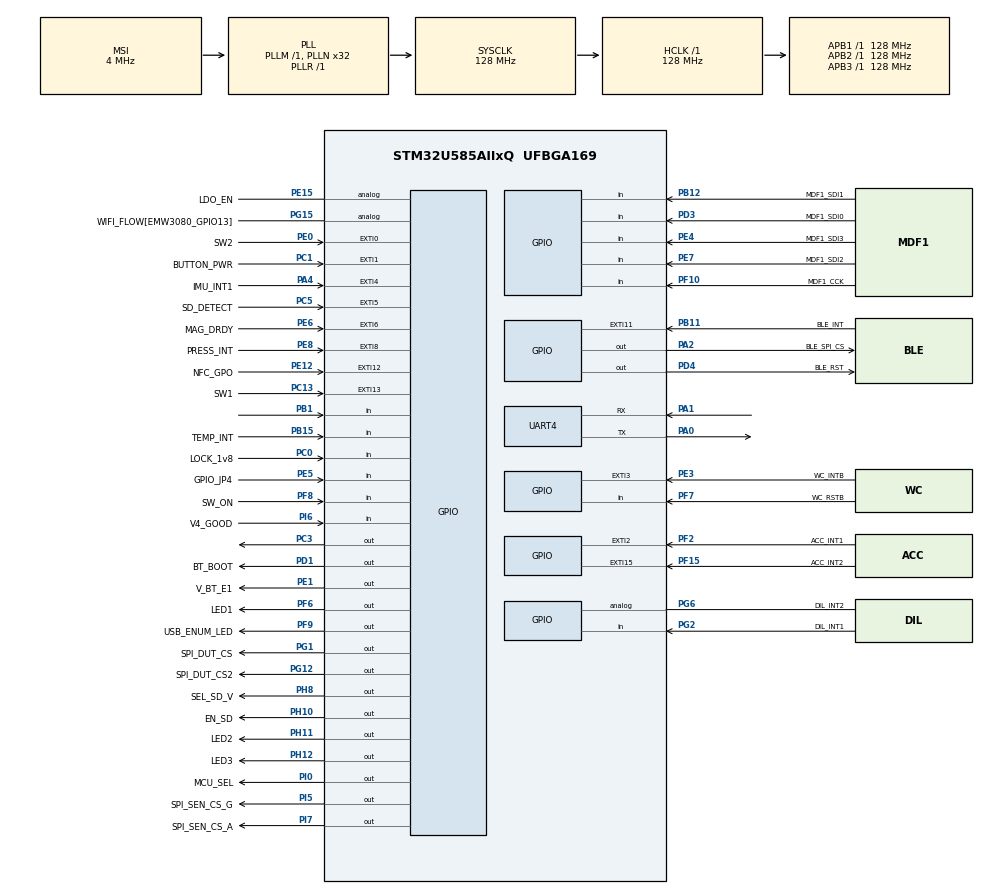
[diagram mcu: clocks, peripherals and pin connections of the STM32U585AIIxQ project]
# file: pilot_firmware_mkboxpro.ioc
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CORTEX_M33_NS.userName=CORTEX_M33
Mcu.Family=STM32U5
Mcu.Name=STM32U585AIIxQ
Mcu.Package=UFBGA169
NVIC.EXTI0_IRQn=true\:7\:0\:true\:false\:true\:true\:true\:false
NVIC.EXTI11_IRQn=true\:0\:0\:false\:false\:true\:true\:true\:true
NVIC.EXTI13_IRQn=true\:0\:0\:false\:false\:true\:true\:true\:true
NVIC.EXTI15_IRQn=true\:7\:0\:true\:false\:true\:true\:true\:false
NVIC.EXTI1_IRQn=true\:7\:0\:true\:false\:true\:true\:true\:false
NVIC.EXTI2_IRQn=true\:7\:0\:true\:false\:true\:true\:true\:false
NVIC.EXTI3_IRQn=true\:7\:0\:true\:false\:true\:true\:true\:false
NVIC.EXTI4_IRQn=true\:7\:0\:true\:false\:true\:true\:true\:false
NVIC.EXTI5_IRQn=true\:7\:0\:true\:false\:true\:true\:true\:false
NVIC.EXTI6_IRQn=true\:7\:0\:true\:false\:true\:true\:true\:false
NVIC.EXTI8_IRQn=true\:7\:0\:true\:false\:true\:true\:true\:true
NVIC.PriorityGroup=NVIC_PRIORITYGROUP_4
PA0.Mode=Asynchronous
PA0.Signal=UART4_TX
PA1.Mode=Asynchronous
PA1.Signal=UART4_RX
PA10.Signal=SAI1_SD_A
PA11.GPIO_Speed=GPIO_SPEED_FREQ_VERY_HIGH
PA11.Signal=USB_OTG_FS_DM
PA12.GPIO_Speed=GPIO_SPEED_FREQ_VERY_HIGH
PA12.PinAttribute=Free
PA12.Signal=USB_OTG_FS_DP
PA13\ (JTMS/SWDIO).Signal=DEBUG_JTMS-SWDIO
PA14\ (JTCK/SWCLK).Signal=DEBUG_JTCK-SWCLK
PA2.GPIO_Label=BLE_SPI_CS
PA2.Signal=GPIO_Output
PA4.GPIO_Label=IMU_INT1
PA4.Signal=GPXTI4
PA5.GPIO_PuPd=GPIO_PULLUP
PA5.GPIO_Speed=GPIO_SPEED_FREQ_HIGH
PA5.Signal=SPI1_SCK
PA6.GPIO_Speed=GPIO_SPEED_FREQ_HIGH
PA6.PinAttribute=Free
PA6.Signal=SPI1_MISO
PA7.GPIO_Speed=GPIO_SPEED_FREQ_HIGH
PA7.Signal=SPI1_MOSI
PA8.Signal=SAI1_SCK_A
PA9.Signal=SAI1_FS_A
PB0.GPIO_Label=VBATT
PB0.Signal=ADC1_IN15
PB1.Signal=GPIO_Input
PB10.Signal=S_TIM2_CH3
PB11.GPIO_Label=BLE_INT
PB11.Signal=GPXTI11
PB12.GPIO_Label=MDF1_SDI1
PB12.Signal=GPIO_Input
PB13.Signal=I2C2_SCL
PB14.Signal=I2C2_SDA
PB15.GPIO_Label=TEMP_INT
PB15.Signal=GPIO_Input
PB3\ (JTDO/TRACESWO).Signal=DEBUG_JTDO-SWO
PB5.GPIO_Speed=GPIO_SPEED_FREQ_HIGH
PB5.Signal=SPI3_MOSI
PB6.Signal=I2C1_SCL
PB7.Signal=UART4_CTS
PB8.Signal=SDMMC1_CKIN
PB9.Signal=SDMMC1_CDIR
PC0.GPIO_Label=LOCK_1v8
PC0.Signal=GPIO_Input
PC1.GPIO_Label=BUTTON_PWR
PC1.Signal=GPXTI1
PC10.Signal=SDMMC1_D2
PC11.Signal=SDMMC1_D3
PC12.Signal=SDMMC1_CK
PC13.GPIO_Label=SW1
PC13.Signal=GPXTI13
PC14-OSC32_IN\ (PC14).Signal=RCC_OSC32_IN
PC15-OSC32_OUT\ (PC15).Signal=RCC_OSC32_OUT
PC3.PinState=GPIO_PIN_SET
PC3.Signal=GPIO_Output
PC5.GPIO_Label=SD_DETECT
PC5.Signal=GPXTI5
PC6.Signal=SDMMC1_D0DIR
PC7.Signal=SDMMC1_D123DIR
PC8.PinAttribute=Free
PC8.Signal=SDMMC1_D0
PC9.PinAttribute=Free
PC9.Signal=SDMMC1_D1
PD1.GPIO_Label=BT_BOOT
PD1.Signal=GPIO_Output
PD12.Signal=I2C4_SCL
PD13.Signal=I2C4_SDA
PD2.Signal=SDMMC1_CMD
PD3.GPIO_Label=MDF1_SDI0
PD3.Signal=GPIO_Input
PD4.GPIO_Label=BLE_RST
PD4.Signal=GPIO_Output
PD5.Signal=USART2_TX
PD6.Signal=USART2_RX
PE0.GPIO_Label=SW2
PE0.Signal=GPXTI0
PE1.GPIO_Label=V_BT_E1
PE1.PinState=GPIO_PIN_SET
PE1.Signal=GPIO_Output
PE10.Signal=ADF1_SDI0
PE12.GPIO_Label=NFC_GPO
PE12.Signal=GPXTI12
PE13.GPIO_Label=PWM_OUT_T1_C3
PE13.Signal=S_TIM1_CH3
PE15.GPIO_Label=LDO_EN
PE15.Signal=GPIO_Analog
PE2.PinAttribute=Free
PE2.Signal=SAI1_MCLK_A
PE3.GPIO_Label=WC_INTB
PE3.Signal=GPXTI3
PE4.GPIO_Label=MDF1_SDI3
PE4.Signal=GPIO_Input
PE5.GPIO_Label=GPIO_JP4
PE5.Signal=GPIO_Input
PE6.GPIO_Label=MAG_DRDY
PE6.Signal=GPXTI6
PE7.GPIO_Label=MDF1_SDI2
PE7.Signal=GPIO_Input
PE8.GPIO_Label=PRESS_INT
PE8.Signal=GPXTI8
PE9.Signal=ADF1_CCK0
PF10.GPIO_Label=MDF1_CCK
PF10.Signal=GPIO_Input
PF15.GPIO_Label=ACC_INT2
PF15.Signal=GPXTI15
PF2.GPIO_Label=ACC_INT1
PF2.GPIO_PuPd=GPIO_PULLDOWN
PF2.Signal=GPXTI2
PF6.GPIO_Label=LED1
PF6.Signal=GPIO_Output
PF7.GPIO_Label=WC_RSTB
PF7.Signal=GPIO_Input
PF8.GPIO_Label=SW_ON
PF8.Signal=GPIO_Input
PF9.GPIO_Label=USB_ENUM_LED
PF9.Signal=GPIO_Output
PG1.GPIO_Label=SPI_DUT_CS
PG1.Signal=GPIO_Output
PG10.GPIO_Speed=GPIO_SPEED_FREQ_HIGH
PG10.Signal=SPI3_MISO
PG12.GPIO_Label=SPI_DUT_CS2
PG12.Signal=GPIO_Output
PG15.GPIO_Label=WIFI_FLOW[EMW3080_GPIO13]
PG15.PinAttribute=Free
PG15.Signal=GPIO_Analog
PG2.GPIO_Label=DIL_INT1
PG2.Signal=GPIO_Input
PG6.GPIO_Label=DIL_INT2
PG6.Signal=GPIO_Analog
PG7.PinAttribute=Free
PG7.Signal=I2C3_SCL
PG8.Signal=I2C3_SDA
PG9.GPIO_PuPd=GPIO_PULLUP
PG9.GPIO_Speed=GPIO_SPEED_FREQ_HIGH
PG9.Signal=SPI3_SCK
PH0-OSC_IN\ (PH0).Signal=RCC_OSC_IN
PH1-OSC_OUT\ (PH1).Signal=RCC_OSC_OUT
PH10.GPIO_Label=EN_SD
PH10.Signal=GPIO_Output
PH11.GPIO_Label=LED2
PH11.Signal=GPIO_Output
PH12.GPIO_Label=LED3
PH12.Signal=GPIO_Output
PH8.GPIO_Label=SEL_SD_V
PH8.Signal=GPIO_Output
PI0.GPIO_Label=MCU_SEL
PI0.PinState=GPIO_PIN_SET
PI0.Signal=GPIO_Output
PI1.GPIO_PuPd=GPIO_PULLUP
PI1.GPIO_Speed=GPIO_SPEED_FREQ_HIGH
PI1.Signal=SPI2_SCK
PI2.GPIO_Speed=GPIO_SPEED_FREQ_HIGH
PI2.Signal=SPI2_MISO
PI3.GPIO_Speed=GPIO_SPEED_FREQ_HIGH
PI3.Signal=SPI2_MOSI
PI5.GPIO_Label=SPI_SEN_CS_G
PI5.PinState=GPIO_PIN_SET
PI5.Signal=GPIO_Output
PI6.GPIO_Label=V4_GOOD
PI6.PinAttribute=Free
PI6.Signal=GPIO_Input
PI7.GPIO_Label=SPI_SEN_CS_A
PI7.PinState=GPIO_PIN_SET
PI7.Signal=GPIO_Output
ProjectManager.HeapSize=0x200
ProjectManager.StackSize=0x400
ProjectManager.TargetToolchain=STM32CubeIDE
RCC.ADCCLockSelection=RCC_ADCDACCLKSOURCE_PLL2
RCC.ADCFreq_Value=3840000
RCC.AHBFreq_Value=128000000
RCC.APB1Freq_Value=128000000
RCC.APB1TimFreq_Value=128000000
RCC.APB2Freq_Value=128000000
RCC.APB2TimFreq_Value=128000000
RCC.APB3Freq_Value=128000000
RCC.AdfClockSelection=RCC_ADF1CLKSOURCE_PLL3
RCC.CortexFreq_Value=128000000
RCC.DACCLockSelectionVirtual=RCC_DAC1CLKSOURCE_LSI
RCC.EPOD_VALUE=4000000
RCC.HCLKFreq_Value=128000000
RCC.HSE_VALUE=16000000
RCC.HSI48_VALUE=48000000
RCC.HSI_VALUE=16000000
RCC.LSE_VALUE=32768
RCC.LSIDIV_VALUE=32000
RCC.MSI_VALUE=4000000
RCC.MdfClockSelection=RCC_MDF1CLKSOURCE_PLL3
RCC.PLL1P=1
RCC.PLL1R=1
RCC.PLL2FRACN=0
RCC.PLL2M=2
RCC.PLL2N=48
RCC.PLL2Q=7
RCC.PLL2R=25
RCC.PLL3FRACN=0
RCC.PLL3M=2
RCC.PLL3N=48
RCC.PLL3Q=25
RCC.PLLFRACN=0
RCC.PLLN=32
RCC.SAI1CLockSelection=RCC_SAI1CLKSOURCE_PLL1
RCC.SDMMCClockSelection=RCC_SDMMCCLKSOURCE_CLK48
RCC.SPI2CLockSelection=RCC_SPI2CLKSOURCE_PCLK1
RCC.SPI3CLockSelection=RCC_SPI3CLKSOURCE_HSI
RCC.SYSCLKFreq_VALUE=128000000
RCC.SYSCLKSource=RCC_SYSCLKSOURCE_PLLCLK
RCC.USBFreq_Value=48000000
RCC.VCOOutputFreq_Value=128000000
RCC.VDD_VALUE=1.8
SH.S_TIM1_CH3.0=TIM1_CH3
SH.S_TIM2_CH3.0=TIM2_CH3
VP_LPBAMQUEUE_VS_QUEUE.Mode=QUEUEMODE
VP_LPBAM_VS_SIG1.Mode=SmartRun
VP_LPBAM_VS_SIG4.Mode=LPDMA1
VP_MEMORYMAP_VS_MEMORYMAP.Mode=CurAppReg
VP_PWR_VS_SECSignals.Mode=Security/Privilege
board=STEVAL-MKBOXPRO

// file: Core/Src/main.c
/* USER CODE BEGIN Header */
/**
  ******************************************************************************
  * @file           : main.c
  * @brief          : Main program body
  ******************************************************************************
  * @attention
  *
  * Copyright (c) 2024 STMicroelectronics.
  * All rights reserved.
  *
  * This software is licensed under terms that can be found in the LICENSE file
  * in the root directory of this software component.
  * If no LICENSE file comes with this software, it is provided AS-IS.
  *
  ******************************************************************************
  */
/* USER CODE END Header */
#include "main.h"

/* USER CODE BEGIN Includes */
#include "main_module.h"

/* USER CODE END Includes */

UART_HandleTypeDef huart4;

void SystemClock_Config(void);
static void MX_GPIO_Init(void);
static void MX_UART4_Init(void);

int main(void)
{

  /* MCU Configuration--------------------------------------------------------*/

  /* Reset of all peripherals, Initializes the Flash interface and the Systick. */
  HAL_Init();

  /* Configure the system clock */
  SystemClock_Config();

  /* Initialize all configured peripherals */
  MX_GPIO_Init();
  MX_UART4_Init();

  /* Infinite loop */
  while (1)
  {

    /* USER CODE BEGIN 3 */
	MM_Process();
  }
  /* USER CODE END 3 */
}

void SystemClock_Config(void)
{
  RCC_OscInitTypeDef RCC_OscInitStruct = {0};
  RCC_ClkInitTypeDef RCC_ClkInitStruct = {0};

  /** Configure the main internal regulator output voltage
  */
  if (HAL_PWREx_ControlVoltageScaling(PWR_REGULATOR_VOLTAGE_SCALE1) != HAL_OK)
  {
    Error_Handler();
  }

  /** Initializes the CPU, AHB and APB buses clocks
  */
  RCC_OscInitStruct.OscillatorType = RCC_OSCILLATORTYPE_MSI;
  RCC_OscInitStruct.MSIState = RCC_MSI_ON;
  RCC_OscInitStruct.MSICalibrationValue = RCC_MSICALIBRATION_DEFAULT;
  RCC_OscInitStruct.MSIClockRange = RCC_MSIRANGE_4;
  RCC_OscInitStruct.PLL.PLLState = RCC_PLL_ON;
  RCC_OscInitStruct.PLL.PLLSource = RCC_PLLSOURCE_MSI;
  RCC_OscInitStruct.PLL.PLLMBOOST = RCC_PLLMBOOST_DIV1;
  RCC_OscInitStruct.PLL.PLLM = 1;
  RCC_OscInitStruct.PLL.PLLN = 32;
  RCC_OscInitStruct.PLL.PLLP = 1;
  RCC_OscInitStruct.PLL.PLLQ = 2;
  RCC_OscInitStruct.PLL.PLLR = 1;
  RCC_OscInitStruct.PLL.PLLRGE = RCC_PLLVCIRANGE_0;
  RCC_OscInitStruct.PLL.PLLFRACN = 0;
  if (HAL_RCC_OscConfig(&RCC_OscInitStruct) != HAL_OK)
  {
    Error_Handler();
  }

  /** Initializes the CPU, AHB and APB buses clocks
  */
  RCC_ClkInitStruct.ClockType = RCC_CLOCKTYPE_HCLK|RCC_CLOCKTYPE_SYSCLK
                              |RCC_CLOCKTYPE_PCLK1|RCC_CLOCKTYPE_PCLK2
                              |RCC_CLOCKTYPE_PCLK3;
  RCC_ClkInitStruct.SYSCLKSource = RCC_SYSCLKSOURCE_PLLCLK;
  RCC_ClkInitStruct.AHBCLKDivider = RCC_SYSCLK_DIV1;
  RCC_ClkInitStruct.APB1CLKDivider = RCC_HCLK_DIV1;
  RCC_ClkInitStruct.APB2CLKDivider = RCC_HCLK_DIV1;
  RCC_ClkInitStruct.APB3CLKDivider = RCC_HCLK_DIV1;

  if (HAL_RCC_ClockConfig(&RCC_ClkInitStruct, FLASH_LATENCY_3) != HAL_OK)
  {
    Error_Handler();
  }
}

static void MX_UART4_Init(void)
{

  huart4.Instance = UART4;
  huart4.Init.BaudRate = 115200;
  huart4.Init.WordLength = UART_WORDLENGTH_8B;
  huart4.Init.StopBits = UART_STOPBITS_1;
  huart4.Init.Parity = UART_PARITY_NONE;
  huart4.Init.Mode = UART_MODE_TX_RX;
  huart4.Init.HwFlowCtl = UART_HWCONTROL_NONE;
  huart4.Init.OverSampling = UART_OVERSAMPLING_16;
  huart4.Init.OneBitSampling = UART_ONE_BIT_SAMPLE_DISABLE;
  huart4.Init.ClockPrescaler = UART_PRESCALER_DIV1;
  huart4.AdvancedInit.AdvFeatureInit = UART_ADVFEATURE_NO_INIT;
  if (HAL_UART_Init(&huart4) != HAL_OK)
  {
    Error_Handler();
  }
  if (HAL_UARTEx_SetTxFifoThreshold(&huart4, UART_TXFIFO_THRESHOLD_1_8) != HAL_OK)
  {
    Error_Handler();
  }
  if (HAL_UARTEx_SetRxFifoThreshold(&huart4, UART_RXFIFO_THRESHOLD_1_8) != HAL_OK)
  {
    Error_Handler();
  }
  if (HAL_UARTEx_DisableFifoMode(&huart4) != HAL_OK)
  {
    Error_Handler();
  }

}

static void MX_GPIO_Init(void)
{
  GPIO_InitTypeDef GPIO_InitStruct = {0};

  /* GPIO Ports Clock Enable */
  __HAL_RCC_GPIOE_CLK_ENABLE();
  __HAL_RCC_GPIOI_CLK_ENABLE();
  __HAL_RCC_GPIOG_CLK_ENABLE();
  __HAL_RCC_GPIOC_CLK_ENABLE();
  __HAL_RCC_GPIOB_CLK_ENABLE();
  __HAL_RCC_GPIOD_CLK_ENABLE();
  __HAL_RCC_GPIOH_CLK_ENABLE();
  __HAL_RCC_GPIOA_CLK_ENABLE();
  __HAL_RCC_GPIOF_CLK_ENABLE();

  /*Configure GPIO pin Output Level */
  HAL_GPIO_WritePin(GPIOI, SPI_SEN_CS_G_Pin|MCU_SEL_Pin|SPI_SEN_CS_A_Pin, GPIO_PIN_SET);

  /*Configure GPIO pin Output Level */
  HAL_GPIO_WritePin(GPIOH, LED3_Pin|EN_SD_Pin|LED2_Pin|SEL_SD_V_Pin, GPIO_PIN_RESET);

  /*Configure GPIO pin Output Level */
  HAL_GPIO_WritePin(V_BT_E1_GPIO_Port, V_BT_E1_Pin, GPIO_PIN_SET);

  /*Configure GPIO pin Output Level */
  HAL_GPIO_WritePin(GPIOD, BLE_RST_Pin|BT_BOOT_Pin, GPIO_PIN_RESET);

  /*Configure GPIO pin Output Level */
  HAL_GPIO_WritePin(GPIOG, SPI_DUT_CS2_Pin|SPI_DUT_CS_Pin, GPIO_PIN_RESET);

  /*Configure GPIO pin Output Level */
  HAL_GPIO_WritePin(GPIOF, USB_ENUM_LED_Pin|LED1_Pin, GPIO_PIN_RESET);

  /*Configure GPIO pin Output Level */
  HAL_GPIO_WritePin(GPIOC, GPIO_PIN_3, GPIO_PIN_SET);

  /*Configure GPIO pin Output Level */
  HAL_GPIO_WritePin(BLE_SPI_CS_GPIO_Port, BLE_SPI_CS_Pin, GPIO_PIN_RESET);

  /*Configure GPIO pin : PE2 */
  GPIO_InitStruct.Pin = GPIO_PIN_2;
  GPIO_InitStruct.Mode = GPIO_MODE_AF_PP;
  GPIO_InitStruct.Pull = GPIO_NOPULL;
  GPIO_InitStruct.Speed = GPIO_SPEED_FREQ_LOW;
  GPIO_InitStruct.Alternate = GPIO_AF13_SAI1;
  HAL_GPIO_Init(GPIOE, &GPIO_InitStruct);

  /*Configure GPIO pin : V4_GOOD_Pin */
  GPIO_InitStruct.Pin = V4_GOOD_Pin;
  GPIO_InitStruct.Mode = GPIO_MODE_INPUT;
  GPIO_InitStruct.Pull = GPIO_NOPULL;
  HAL_GPIO_Init(V4_GOOD_GPIO_Port, &GPIO_InitStruct);

  /*Configure GPIO pins : WIFI_FLOW_Pin DIL_INT2_Pin */
  GPIO_InitStruct.Pin = WIFI_FLOW_Pin|DIL_INT2_Pin;
  GPIO_InitStruct.Mode = GPIO_MODE_ANALOG;
  GPIO_InitStruct.Pull = GPIO_NOPULL;
  HAL_GPIO_Init(GPIOG, &GPIO_InitStruct);

  /*Configure GPIO pin : PG9 */
  GPIO_InitStruct.Pin = GPIO_PIN_9;
  GPIO_InitStruct.Mode = GPIO_MODE_AF_PP;
  GPIO_InitStruct.Pull = GPIO_PULLUP;
  GPIO_InitStruct.Speed = GPIO_SPEED_FREQ_HIGH;
  GPIO_InitStruct.Alternate = GPIO_AF6_SPI3;
  HAL_GPIO_Init(GPIOG, &GPIO_InitStruct);

  /*Configure GPIO pins : PC11 PC10 PC12 PC9
                           PC8 */
  GPIO_InitStruct.Pin = GPIO_PIN_11|GPIO_PIN_10|GPIO_PIN_12|GPIO_PIN_9
                          |GPIO_PIN_8;
  GPIO_InitStruct.Mode = GPIO_MODE_AF_PP;
  GPIO_InitStruct.Pull = GPIO_NOPULL;
  GPIO_InitStruct.Speed = GPIO_SPEED_FREQ_HIGH;
  GPIO_InitStruct.Alternate = GPIO_AF12_SDMMC1;
  HAL_GPIO_Init(GPIOC, &GPIO_InitStruct);

  /*Configure GPIO pin : PI1 */
  GPIO_InitStruct.Pin = GPIO_PIN_1;
  GPIO_InitStruct.Mode = GPIO_MODE_AF_PP;
  GPIO_InitStruct.Pull = GPIO_PULLUP;
  GPIO_InitStruct.Speed = GPIO_SPEED_FREQ_HIGH;
  GPIO_InitStruct.Alternate = GPIO_AF5_SPI2;
  HAL_GPIO_Init(GPIOI, &GPIO_InitStruct);

  /*Configure GPIO pins : SPI_SEN_CS_G_Pin MCU_SEL_Pin SPI_SEN_CS_A_Pin */
  GPIO_InitStruct.Pin = SPI_SEN_CS_G_Pin|MCU_SEL_Pin|SPI_SEN_CS_A_Pin;
  GPIO_InitStruct.Mode = GPIO_MODE_OUTPUT_PP;
  GPIO_InitStruct.Pull = GPIO_NOPULL;
  GPIO_InitStruct.Speed = GPIO_SPEED_FREQ_LOW;
  HAL_GPIO_Init(GPIOI, &GPIO_InitStruct);

  /*Configure GPIO pin : PB6 */
  GPIO_InitStruct.Pin = GPIO_PIN_6;
  GPIO_InitStruct.Mode = GPIO_MODE_AF_OD;
  GPIO_InitStruct.Pull = GPIO_NOPULL;
  GPIO_InitStruct.Speed = GPIO_SPEED_FREQ_LOW;
  GPIO_InitStruct.Alternate = GPIO_AF4_I2C1;
  HAL_GPIO_Init(GPIOB, &GPIO_InitStruct);

  /*Configure GPIO pins : PD6 PD5 */
  GPIO_InitStruct.Pin = GPIO_PIN_6|GPIO_PIN_5;
  GPIO_InitStruct.Mode = GPIO_MODE_AF_PP;
  GPIO_InitStruct.Pull = GPIO_NOPULL;
  GPIO_InitStruct.Speed = GPIO_SPEED_FREQ_LOW;
  GPIO_InitStruct.Alternate = GPIO_AF7_USART2;
  HAL_GPIO_Init(GPIOD, &GPIO_InitStruct);

  /*Configure GPIO pins : LED3_Pin EN_SD_Pin LED2_Pin SEL_SD_V_Pin */
  GPIO_InitStruct.Pin = LED3_Pin|EN_SD_Pin|LED2_Pin|SEL_SD_V_Pin;
  GPIO_InitStruct.Mode = GPIO_MODE_OUTPUT_PP;
  GPIO_InitStruct.Pull = GPIO_NOPULL;
  GPIO_InitStruct.Speed = GPIO_SPEED_FREQ_LOW;
  HAL_GPIO_Init(GPIOH, &GPIO_InitStruct);

  /*Configure GPIO pins : MDF1_SDI3_Pin GPIO_JP4_Pin MDF1_SDI2_Pin */
  GPIO_InitStruct.Pin = MDF1_SDI3_Pin|GPIO_JP4_Pin|MDF1_SDI2_Pin;
  GPIO_InitStruct.Mode = GPIO_MODE_INPUT;
  GPIO_InitStruct.Pull = GPIO_NOPULL;
  HAL_GPIO_Init(GPIOE, &GPIO_InitStruct);

  /*Configure GPIO pin : V_BT_E1_Pin */
  GPIO_InitStruct.Pin = V_BT_E1_Pin;
  GPIO_InitStruct.Mode = GPIO_MODE_OUTPUT_PP;
  GPIO_InitStruct.Pull = GPIO_NOPULL;
  GPIO_InitStruct.Speed = GPIO_SPEED_FREQ_LOW;
  HAL_GPIO_Init(V_BT_E1_GPIO_Port, &GPIO_InitStruct);

  /*Configure GPIO pin : PB5 */
  GPIO_InitStruct.Pin = GPIO_PIN_5;
  GPIO_InitStruct.Mode = GPIO_MODE_AF_PP;
  GPIO_InitStruct.Pull = GPIO_NOPULL;
  GPIO_InitStruct.Speed = GPIO_SPEED_FREQ_HIGH;
  GPIO_InitStruct.Alternate = GPIO_AF6_SPI3;
  HAL_GPIO_Init(GPIOB, &GPIO_InitStruct);

  /*Configure GPIO pin : PG10 */
  GPIO_InitStruct.Pin = GPIO_PIN_10;
  GPIO_InitStruct.Mode = GPIO_MODE_AF_PP;
  GPIO_InitStruct.Pull = GPIO_NOPULL;
  GPIO_InitStruct.Speed = GPIO_SPEED_FREQ_HIGH;
  GPIO_InitStruct.Alternate = GPIO_AF6_SPI3;
  HAL_GPIO_Init(GPIOG, &GPIO_InitStruct);

  /*Configure GPIO pins : BLE_RST_Pin BT_BOOT_Pin */
  GPIO_InitStruct.Pin = BLE_RST_Pin|BT_BOOT_Pin;
  GPIO_InitStruct.Mode = GPIO_MODE_OUTPUT_PP;
  GPIO_InitStruct.Pull = GPIO_NOPULL;
  GPIO_InitStruct.Speed = GPIO_SPEED_FREQ_LOW;
  HAL_GPIO_Init(GPIOD, &GPIO_InitStruct);

  /*Configure GPIO pins : WC_INTB_Pin SW2_Pin MAG_DRDY_Pin PRESS_INT_Pin
                           NFC_GPO_Pin */
  GPIO_InitStruct.Pin = WC_INTB_Pin|SW2_Pin|MAG_DRDY_Pin|PRESS_INT_Pin
                          |NFC_GPO_Pin;
  GPIO_InitStruct.Mode = GPIO_MODE_IT_RISING;
  GPIO_InitStruct.Pull = GPIO_NOPULL;
  HAL_GPIO_Init(GPIOE, &GPIO_InitStruct);

  /*Configure GPIO pins : PB9 PB8 */
  GPIO_InitStruct.Pin = GPIO_PIN_9|GPIO_PIN_8;
  GPIO_InitStruct.Mode = GPIO_MODE_AF_PP;
  GPIO_InitStruct.Pull = GPIO_NOPULL;
  GPIO_InitStruct.Speed = GPIO_SPEED_FREQ_HIGH;
  GPIO_InitStruct.Alternate = GPIO_AF8_SDMMC1;
  HAL_GPIO_Init(GPIOB, &GPIO_InitStruct);

  /*Configure GPIO pin : MDF1_SDI0_Pin */
  GPIO_InitStruct.Pin = MDF1_SDI0_Pin;
  GPIO_InitStruct.Mode = GPIO_MODE_INPUT;
  GPIO_InitStruct.Pull = GPIO_NOPULL;
  HAL_GPIO_Init(MDF1_SDI0_GPIO_Port, &GPIO_InitStruct);

  /*Configure GPIO pins : PI3 PI2 */
  GPIO_InitStruct.Pin = GPIO_PIN_3|GPIO_PIN_2;
  GPIO_InitStruct.Mode = GPIO_MODE_AF_PP;
  GPIO_InitStruct.Pull = GPIO_NOPULL;
  GPIO_InitStruct.Speed = GPIO_SPEED_FREQ_HIGH;
  GPIO_InitStruct.Alternate = GPIO_AF5_SPI2;
  HAL_GPIO_Init(GPIOI, &GPIO_InitStruct);

  /*Configure GPIO pins : SW1_Pin BUTTON_PWR_Pin SD_DETECT_Pin */
  GPIO_InitStruct.Pin = SW1_Pin|BUTTON_PWR_Pin|SD_DETECT_Pin;
  GPIO_InitStruct.Mode = GPIO_MODE_IT_RISING;
  GPIO_InitStruct.Pull = GPIO_NOPULL;
  HAL_GPIO_Init(GPIOC, &GPIO_InitStruct);

  /*Configure GPIO pins : SPI_DUT_CS2_Pin SPI_DUT_CS_Pin */
  GPIO_InitStruct.Pin = SPI_DUT_CS2_Pin|SPI_DUT_CS_Pin;
  GPIO_InitStruct.Mode = GPIO_MODE_OUTPUT_PP;
  GPIO_InitStruct.Pull = GPIO_NOPULL;
  GPIO_InitStruct.Speed = GPIO_SPEED_FREQ_LOW;
  HAL_GPIO_Init(GPIOG, &GPIO_InitStruct);

  /*Configure GPIO pins : SW_ON_Pin WC_RSTB_Pin MDF1_CCK_Pin */
  GPIO_InitStruct.Pin = SW_ON_Pin|WC_RSTB_Pin|MDF1_CCK_Pin;
  GPIO_InitStruct.Mode = GPIO_MODE_INPUT;
  GPIO_InitStruct.Pull = GPIO_NOPULL;
  HAL_GPIO_Init(GPIOF, &GPIO_InitStruct);

  /*Configure GPIO pin : ACC_INT1_Pin */
  GPIO_InitStruct.Pin = ACC_INT1_Pin;
  GPIO_InitStruct.Mode = GPIO_MODE_IT_RISING;
  GPIO_InitStruct.Pull = GPIO_PULLDOWN;
  HAL_GPIO_Init(ACC_INT1_GPIO_Port, &GPIO_InitStruct);

  /*Configure GPIO pin : PD2 */
  GPIO_InitStruct.Pin = GPIO_PIN_2;
  GPIO_InitStruct.Mode = GPIO_MODE_AF_PP;
  GPIO_InitStruct.Pull = GPIO_NOPULL;
  GPIO_InitStruct.Speed = GPIO_SPEED_FREQ_HIGH;
  GPIO_InitStruct.Alternate = GPIO_AF12_SDMMC1;
  HAL_GPIO_Init(GPIOD, &GPIO_InitStruct);

  /*Configure GPIO pins : PA10 PA8 PA9 */
  GPIO_InitStruct.Pin = GPIO_PIN_10|GPIO_PIN_8|GPIO_PIN_9;
  GPIO_InitStruct.Mode = GPIO_MODE_AF_PP;
  GPIO_InitStruct.Pull = GPIO_NOPULL;
  GPIO_InitStruct.Speed = GPIO_SPEED_FREQ_LOW;
  GPIO_InitStruct.Alternate = GPIO_AF13_SAI1;
  HAL_GPIO_Init(GPIOA, &GPIO_InitStruct);

  /*Configure GPIO pins : PA12 PA11 */
  GPIO_InitStruct.Pin = GPIO_PIN_12|GPIO_PIN_11;
  GPIO_InitStruct.Mode = GPIO_MODE_AF_PP;
  GPIO_InitStruct.Pull = GPIO_NOPULL;
  GPIO_InitStruct.Speed = GPIO_SPEED_FREQ_VERY_HIGH;
  GPIO_InitStruct.Alternate = GPIO_AF10_USB;
  HAL_GPIO_Init(GPIOA, &GPIO_InitStruct);

  /*Configure GPIO pins : USB_ENUM_LED_Pin LED1_Pin */
  GPIO_InitStruct.Pin = USB_ENUM_LED_Pin|LED1_Pin;
  GPIO_InitStruct.Mode = GPIO_MODE_OUTPUT_PP;
  GPIO_InitStruct.Pull = GPIO_NOPULL;
  GPIO_InitStruct.Speed = GPIO_SPEED_FREQ_LOW;
  HAL_GPIO_Init(GPIOF, &GPIO_InitStruct);

  /*Configure GPIO pins : PG7 PG8 */
  GPIO_InitStruct.Pin = GPIO_PIN_7|GPIO_PIN_8;
  GPIO_InitStruct.Mode = GPIO_MODE_AF_OD;
  GPIO_InitStruct.Pull = GPIO_NOPULL;
  GPIO_InitStruct.Speed = GPIO_SPEED_FREQ_LOW;
  GPIO_InitStruct.Alternate = GPIO_AF4_I2C3;
  HAL_GPIO_Init(GPIOG, &GPIO_InitStruct);

  /*Configure GPIO pins : PC7 PC6 */
  GPIO_InitStruct.Pin = GPIO_PIN_7|GPIO_PIN_6;
  GPIO_InitStruct.Mode = GPIO_MODE_AF_PP;
  GPIO_InitStruct.Pull = GPIO_NOPULL;
  GPIO_InitStruct.Speed = GPIO_SPEED_FREQ_HIGH;
  GPIO_InitStruct.Alternate = GPIO_AF8_SDMMC1;
  HAL_GPIO_Init(GPIOC, &GPIO_InitStruct);

  /*Configure GPIO pins : PE10 PE9 */
  GPIO_InitStruct.Pin = GPIO_PIN_10|GPIO_PIN_9;
  GPIO_InitStruct.Mode = GPIO_MODE_AF_PP;
  GPIO_InitStruct.Pull = GPIO_NOPULL;
  GPIO_InitStruct.Speed = GPIO_SPEED_FREQ_LOW;
  GPIO_InitStruct.Alternate = GPIO_AF3_ADF1;
  HAL_GPIO_Init(GPIOE, &GPIO_InitStruct);

  /*Configure GPIO pin : LOCK_1v8_Pin */
  GPIO_InitStruct.Pin = LOCK_1v8_Pin;
  GPIO_InitStruct.Mode = GPIO_MODE_INPUT;
  GPIO_InitStruct.Pull = GPIO_NOPULL;
  HAL_GPIO_Init(LOCK_1v8_GPIO_Port, &GPIO_InitStruct);

  /*Configure GPIO pins : PA7 PA6 */
  GPIO_InitStruct.Pin = GPIO_PIN_7|GPIO_PIN_6;
  GPIO_InitStruct.Mode = GPIO_MODE_AF_PP;
  GPIO_InitStruct.Pull = GPIO_NOPULL;
  GPIO_InitStruct.Speed = GPIO_SPEED_FREQ_HIGH;
  GPIO_InitStruct.Alternate = GPIO_AF5_SPI1;
  HAL_GPIO_Init(GPIOA, &GPIO_InitStruct);

  /*Configure GPIO pin : PC3 */
  GPIO_InitStruct.Pin = GPIO_PIN_3;
  GPIO_InitStruct.Mode = GPIO_MODE_OUTPUT_PP;
  GPIO_InitStruct.Pull = GPIO_NOPULL;
  GPIO_InitStruct.Speed = GPIO_SPEED_FREQ_LOW;
  HAL_GPIO_Init(GPIOC, &GPIO_InitStruct);

  /*Configure GPIO pin : PA5 */
  GPIO_InitStruct.Pin = GPIO_PIN_5;
  GPIO_InitStruct.Mode = GPIO_MODE_AF_PP;
  GPIO_InitStruct.Pull = GPIO_PULLUP;
  GPIO_InitStruct.Speed = GPIO_SPEED_FREQ_HIGH;
  GPIO_InitStruct.Alternate = GPIO_AF5_SPI1;
  HAL_GPIO_Init(GPIOA, &GPIO_InitStruct);

  /*Configure GPIO pin : VBATT_Pin */
  GPIO_InitStruct.Pin = VBATT_Pin;
  GPIO_InitStruct.Mode = GPIO_MODE_ANALOG;
  GPIO_InitStruct.Pull = GPIO_NOPULL;
  HAL_GPIO_Init(VBATT_GPIO_Port, &GPIO_InitStruct);

  /*Configure GPIO pin : PB10 */
  GPIO_InitStruct.Pin = GPIO_PIN_10;
  GPIO_InitStruct.Mode = GPIO_MODE_AF_PP;
  GPIO_InitStruct.Pull = GPIO_NOPULL;
  GPIO_InitStruct.Speed = GPIO_SPEED_FREQ_LOW;
  GPIO_InitStruct.Alternate = GPIO_AF1_TIM2;
  HAL_GPIO_Init(GPIOB, &GPIO_InitStruct);

  /*Configure GPIO pins : PD12 PD13 */
  GPIO_InitStruct.Pin = GPIO_PIN_12|GPIO_PIN_13;
  GPIO_InitStruct.Mode = GPIO_MODE_AF_OD;
  GPIO_InitStruct.Pull = GPIO_NOPULL;
  GPIO_InitStruct.Speed = GPIO_SPEED_FREQ_LOW;
  GPIO_InitStruct.Alternate = GPIO_AF4_I2C4;
  HAL_GPIO_Init(GPIOD, &GPIO_InitStruct);

  /*Configure GPIO pin : DIL_INT1_Pin */
  GPIO_InitStruct.Pin = DIL_INT1_Pin;
  GPIO_InitStruct.Mode = GPIO_MODE_INPUT;
  GPIO_InitStruct.Pull = GPIO_NOPULL;
  HAL_GPIO_Init(DIL_INT1_GPIO_Port, &GPIO_InitStruct);

  /*Configure GPIO pin : PWM_OUT_T1_C3_Pin */
  GPIO_InitStruct.Pin = PWM_OUT_T1_C3_Pin;
  GPIO_InitStruct.Mode = GPIO_MODE_AF_PP;
  GPIO_InitStruct.Pull = GPIO_NOPULL;
  GPIO_InitStruct.Speed = GPIO_SPEED_FREQ_LOW;
  GPIO_InitStruct.Alternate = GPIO_AF1_TIM1;
  HAL_GPIO_Init(PWM_OUT_T1_C3_GPIO_Port, &GPIO_InitStruct);

  /*Configure GPIO pin : BLE_INT_Pin */
  GPIO_InitStruct.Pin = BLE_INT_Pin;
  GPIO_InitStruct.Mode = GPIO_MODE_IT_RISING;
  GPIO_InitStruct.Pull = GPIO_NOPULL;
  HAL_GPIO_Init(BLE_INT_GPIO_Port, &GPIO_InitStruct);

  /*Configure GPIO pins : MDF1_SDI1_Pin TEMP_INT_Pin PB1 */
  GPIO_InitStruct.Pin = MDF1_SDI1_Pin|TEMP_INT_Pin|GPIO_PIN_1;
  GPIO_InitStruct.Mode = GPIO_MODE_INPUT;
  GPIO_InitStruct.Pull = GPIO_NOPULL;
  HAL_GPIO_Init(GPIOB, &GPIO_InitStruct);

  /*Configure GPIO pin : BLE_SPI_CS_Pin */
  GPIO_InitStruct.Pin = BLE_SPI_CS_Pin;
  GPIO_InitStruct.Mode = GPIO_MODE_OUTPUT_PP;
  GPIO_InitStruct.Pull = GPIO_NOPULL;
  GPIO_InitStruct.Speed = GPIO_SPEED_FREQ_LOW;
  HAL_GPIO_Init(BLE_SPI_CS_GPIO_Port, &GPIO_InitStruct);

  /*Configure GPIO pin : LDO_EN_Pin */
  GPIO_InitStruct.Pin = LDO_EN_Pin;
  GPIO_InitStruct.Mode = GPIO_MODE_ANALOG;
  GPIO_InitStruct.Pull = GPIO_NOPULL;
  HAL_GPIO_Init(LDO_EN_GPIO_Port, &GPIO_InitStruct);

  /*Configure GPIO pins : PB14 PB13 */
  GPIO_InitStruct.Pin = GPIO_PIN_14|GPIO_PIN_13;
  GPIO_InitStruct.Mode = GPIO_MODE_AF_OD;
  GPIO_InitStruct.Pull = GPIO_NOPULL;
  GPIO_InitStruct.Speed = GPIO_SPEED_FREQ_LOW;
  GPIO_InitStruct.Alternate = GPIO_AF4_I2C2;
  HAL_GPIO_Init(GPIOB, &GPIO_InitStruct);

  /*Configure GPIO pin : IMU_INT1_Pin */
  GPIO_InitStruct.Pin = IMU_INT1_Pin;
  GPIO_InitStruct.Mode = GPIO_MODE_IT_RISING;
  GPIO_InitStruct.Pull = GPIO_NOPULL;
  HAL_GPIO_Init(IMU_INT1_GPIO_Port, &GPIO_InitStruct);

  /*Configure GPIO pin : ACC_INT2_Pin */
  GPIO_InitStruct.Pin = ACC_INT2_Pin;
  GPIO_InitStruct.Mode = GPIO_MODE_IT_RISING;
  GPIO_InitStruct.Pull = GPIO_NOPULL;
  HAL_GPIO_Init(ACC_INT2_GPIO_Port, &GPIO_InitStruct);

  /* EXTI interrupt init*/
  HAL_NVIC_SetPriority(EXTI0_IRQn, 7, 0);
  HAL_NVIC_SetPriority(EXTI1_IRQn, 7, 0);
  HAL_NVIC_SetPriority(EXTI2_IRQn, 7, 0);
  HAL_NVIC_SetPriority(EXTI3_IRQn, 7, 0);
  HAL_NVIC_SetPriority(EXTI4_IRQn, 7, 0);
  HAL_NVIC_SetPriority(EXTI5_IRQn, 7, 0);
  HAL_NVIC_SetPriority(EXTI6_IRQn, 7, 0);
  HAL_NVIC_SetPriority(EXTI8_IRQn, 7, 0);
  HAL_NVIC_EnableIRQ(EXTI8_IRQn);

  HAL_NVIC_SetPriority(EXTI11_IRQn, 0, 0);
  HAL_NVIC_EnableIRQ(EXTI11_IRQn);

  HAL_NVIC_SetPriority(EXTI13_IRQn, 0, 0);
  HAL_NVIC_EnableIRQ(EXTI13_IRQn);

  HAL_NVIC_SetPriority(EXTI15_IRQn, 7, 0);

}

void Error_Handler(void)
{
  __disable_irq();
  while (1)
  {
  }
}
